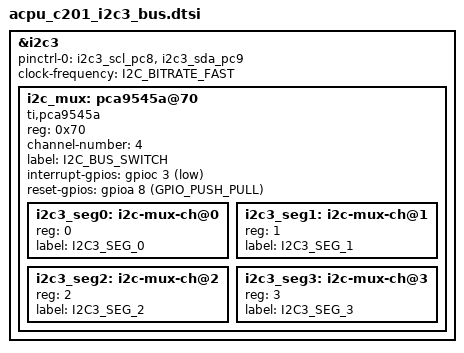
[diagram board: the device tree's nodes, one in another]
/*
 * Copyright (c) 2021 Acme CPU
 *
 */


&i2c3 {
	status = "okay";
	pinctrl-0 = <&i2c3_scl_pc8 &i2c3_sda_pc9>;
	pinctrl-names = "default";
	clock-frequency = <I2C_BITRATE_FAST>;
/*
  compatible = "st,stm32-i2c-dma-v2";
  dmas = <&dma1 0 0 0x0 0x0>,
	 <&dma1 0 0 0x0 0x0>;
  dma-names = "tx","rx";
  dma-label-tx = "DMA_TX_I2C_3";
  dma-label-rx = "DMA_RX_I2C_3";
*/

    i2c_mux: pca9545a@70 {
      compatible = "ti,pca9545a";
      reg = <0x70>;
      channel-number = <4>;
      label = "I2C_BUS_SWITCH";
      #address-cells = <1>;
      #size-cells = <0>;
      #gpio-cells = <2>;

      interrupt-gpios = <&gpioc 3 (GPIO_PULL_UP | GPIO_ACTIVE_LOW)>;
      reset-gpios = <&gpioa 8 (GPIO_PUSH_PULL)>;
  
      i2c3_seg0: i2c-mux-ch@0 {
        #address-cells = <1>;
        #size-cells = <0>;
        reg = <0>;
        label = "I2C3_SEG_0";
      };

      i2c3_seg1: i2c-mux-ch@1 {
        #address-cells = <1>;
        #size-cells = <0>;
        reg = <1>;
        label = "I2C3_SEG_1";
      };
  
      i2c3_seg2: i2c-mux-ch@2 {
        #address-cells = <1>;
        #size-cells = <0>;
        reg = <2>;
        label = "I2C3_SEG_2";
      };

      i2c3_seg3: i2c-mux-ch@3 {
        #address-cells = <1>;
        #size-cells = <0>;
        reg = <3>;
        label = "I2C3_SEG_3";
      };

    };
};
